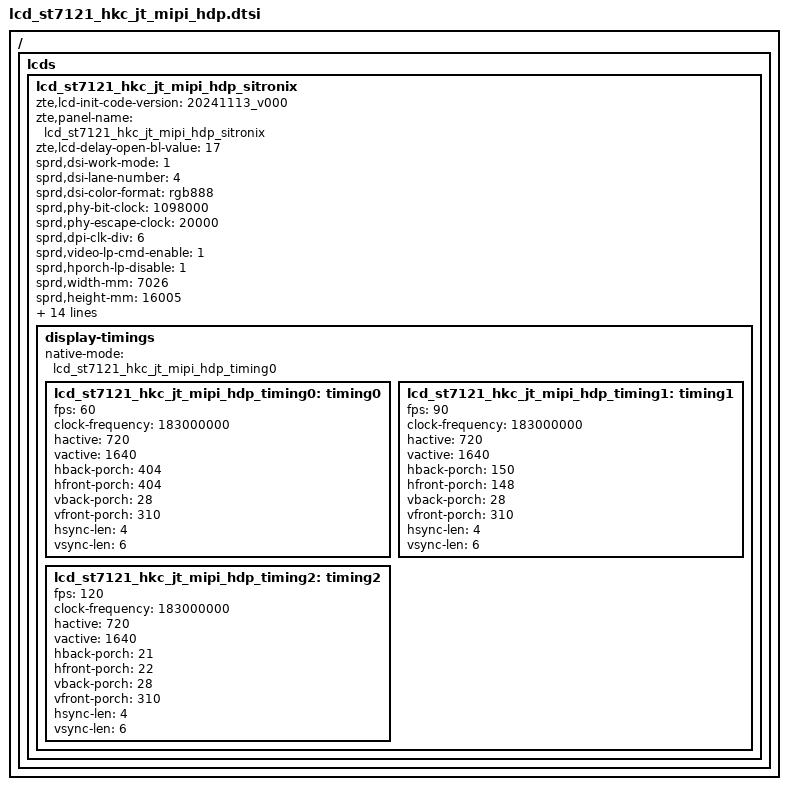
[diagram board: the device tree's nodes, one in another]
/ { 
	fragment {
		target-path = "/";
		__overlay__ {
			lcds {
				lcd_st7121_hkc_jt_mipi_hdp_sitronix: lcd_st7121_hkc_jt_mipi_hdp_sitronix {
		zte,lcd-init-code-version = "20241113_v000";
		zte,panel-name = "lcd_st7121_hkc_jt_mipi_hdp_sitronix";
		zte,lcd-delay-open-bl-value = <17>;

					sprd,dsi-work-mode = <1>;
					sprd,dsi-lane-number = <4>;
					sprd,dsi-color-format = "rgb888";

					sprd,phy-bit-clock = <1098000>;
					sprd,phy-escape-clock = <20000>;
					sprd,dpi-clk-div = <6>;
					sprd,video-lp-cmd-enable = <1>;
					sprd,hporch-lp-disable = <1>;
					sprd,width-mm = <7026>;/*zte mod for 6.67*/
					sprd,height-mm = <16005>;/*zte mod for 6.67*/
					sprd,esd-check-enable = <1>;/*esd enable:1*/
					sprd,esd-check-mode = <1>;/*esd te mode:1*/
					sprd,esd-check-period = <2000>;
					//sprd,esd-check-register = <0x0A>;
					//sprd,esd-check-value = <0x9C>;

					sprd,lcm-ic-name = "ST7121";
					sprd,lcm-ic-vendor = "JT-HKC";
					sprd,lcm-ic-inch = "6.88";

					sprd,reset-on-sequence = <1 5>, <0 5>, <1 120>;
					sprd,reset-off-sequence = <1 5>;


					sprd,initial-command = [
39 00 00 04 60 71 21 a2 
39 00 00 04 60 71 21 a3 
39 00 00 04 60 71 21 a4 

23 00 00 02 78 21 
23 00 00 02 79 CF 
39 00 00 0B 86 25 19 C0 15 F5 01 00 25 D9 15 
39 00 00 05 B7 00 00 73 73 

39 00 00 08 B0 22 75 11 7F 25 39 39 

23 00 00 02 BF A0 

23 00 00 02 A4 33 

39 00 00 03 BB 29 07 

39 00 00 07 D7 10 22 36 3B 34 34 

39 00 00 08 90 71 23 5A 20 24 03 28 

39 00 00 28 A3 80 01 88 FF 45 00 00 00 00 00 46 00 00 1E 5C 1E 80 00 00 05 00 00 00 00 00 46 00 00 1E 5C 1E 80 00 20 58 00 00 00 FF 

39 00 00 38 A6 02 00 24 99 2F 00 32 00 39 39 91 FF 00 24 99 30 00 31 00 39 39 91 FF 00 24 11 00 00 00 00 39 39 91 FF 00 AC 91 00 1B 00 00 39 39 FF FF 00 08 80 08 80 06 00 00 00 00

39 00 00 3D A7 12 12 C0 64 40 0F 1E 41 02 50 0F 39 39 91 FF 08 80 64 40 2D 3C 43 04 0E 0D 39 39 91 FF 08 80 64 40 4B 5A 45 06 0C 0B 39 39 91 FF 08 80 64 40 69 78 07 08 2A 09 39 39 91 FF 08 80 79

39 00 00 2D AC 1D 1D 06 06 1E 1E 06 06 09 0B 0D 0F 16 14 12 10 01 02 00 00 00 00 1D 1D 06 06 1E 1E 06 06 08 0A 0C 0E 17 15 13 11 03 00 00 00 00 00 

39 00 00 1A AD 0C 40 46 00 07 4B 4B FF FF F0 40 0E 01 07 42 42 FF FF 01 00 00 FF FF FF FF 

39 00 00 08 AE FF FF 03 FF FF 03 00 

39 00 00 12 B2 15 19 05 23 49 AF 03 2E 5C D2 FF 10 60 FD 20 C0 00 

39 00 00 0F E8 20 67 04 69 69 3E 04 DC DC 3E 06 FA 26 3E 

39 00 00 03 75 03 04 

39 00 00 2B E7 4B 00 00 BC 4B 8C 20 1A F0 7D 14 7D 14 7D 14 7D 14 FF 00 32 30 73 00 00 C8 6A FF 5A 64 38 88 15 B1 01 01 64 01 01 7C FF 1A 01 

39 00 00 03 E1 0C 0C 

39 00 00 04 EA 15 00 55 

39 00 00 03 62 30 50 

39 00 00 26 C8 00 00 0D 18 2F 00 59 02 96 04 10 ED 06 5D 02 11 A9 02 EB 00 22 2A 0E 71 09 32 D9 0B 2F 0C F3 75 0E AB D6 03 FF 
39 00 00 26 C9 00 00 0D 18 2F 00 59 02 96 04 10 ED 06 5D 02 11 A9 02 EB 00 22 2A 0E 71 09 32 D9 0B 2F 0C F3 75 0E AB D6 03 FF 

39 00 00 03 A5 F0 03 

39 00 00 04 60 71 21 00 

23 00 00 02 35 00 
23 96 00 02 11 00 
23 0A 00 02 29 00 
					];
					sprd,sleep-in-command = [
						13 32 00 01 28
						13 96 00 01 10
					];
					sprd,sleep-out-command = [
						13 96 00 01 11
						13 32 00 01 29
					];

					display-timings {
						native-mode = <&lcd_st7121_hkc_jt_mipi_hdp_timing0>;
						lcd_st7121_hkc_jt_mipi_hdp_timing0: timing0 {
							fps = <60>;
							clock-frequency = <183000000>;
							hactive = <720>;
							vactive = <1640>;
							hback-porch = <404>;
							hfront-porch = <404>;
							vback-porch = <28>;
							vfront-porch = <310>;
							hsync-len = <4>;
							vsync-len = <6>;
						};
						lcd_st7121_hkc_jt_mipi_hdp_timing1: timing1 {
							fps = <90>;
							clock-frequency = <183000000>;
							hactive = <720>;
							vactive = <1640>;
							hback-porch = <150>;
							hfront-porch = <148>;
							vback-porch = <28>;
							vfront-porch = <310>;
							hsync-len = <4>;
							vsync-len = <6>;
						};
						lcd_st7121_hkc_jt_mipi_hdp_timing2: timing2 {
							fps = <120>;
							clock-frequency = <183000000>;
							hactive = <720>;
							vactive = <1640>;
							hback-porch = <21>;
							hfront-porch = <22>;
							vback-porch = <28>;
							vfront-porch = <310>;
							hsync-len = <4>;
							vsync-len = <6>;
						};
					};
				};
			};
		};
	};
};
